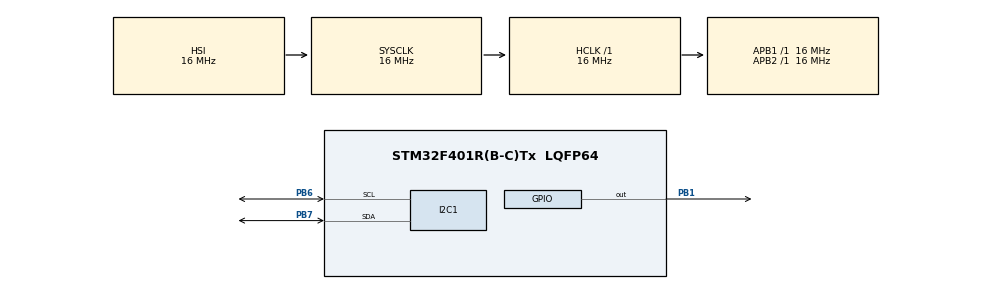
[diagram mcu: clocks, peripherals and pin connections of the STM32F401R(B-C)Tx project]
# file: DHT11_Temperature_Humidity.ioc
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Mcu.Family=STM32F4
Mcu.Name=STM32F401R(B-C)Tx
Mcu.Package=LQFP64
NVIC.PriorityGroup=NVIC_PRIORITYGROUP_4
PA13.Mode=Serial_Wire
PA13.Signal=SYS_JTMS-SWDIO
PA14.Mode=Serial_Wire
PA14.Signal=SYS_JTCK-SWCLK
PB1.Signal=GPIO_Output
PB6.Mode=I2C
PB6.Signal=I2C1_SCL
PB7.Mode=I2C
PB7.Signal=I2C1_SDA
ProjectManager.HeapSize=0x200
ProjectManager.StackSize=0x400
ProjectManager.TargetToolchain=STM32CubeIDE
RCC.AHBFreq_Value=16000000
RCC.APB1Freq_Value=16000000
RCC.APB2Freq_Value=16000000
RCC.CortexFreq_Value=16000000
RCC.HSE_VALUE=25000000
RCC.HSI_VALUE=16000000
RCC.LSE_VALUE=32768
RCC.SYSCLKFreq_VALUE=16000000
RCC.VCOOutputFreq_Value=192000000
TIM2.Period=65535
TIM2.Prescaler=15
VP_TIM2_VS_ClockSourceINT.Mode=Internal
board=custom

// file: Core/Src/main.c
/* USER CODE BEGIN Header */
/**
  ******************************************************************************
  * @file           : main.c
  * @brief          : Main program body
  ******************************************************************************
  * @attention
  *
  * Copyright (c) 2026 STMicroelectronics.
  * All rights reserved.
  *
  * This software is licensed under terms that can be found in the LICENSE file
  * in the root directory of this software component.
  * If no LICENSE file comes with this software, it is provided AS-IS.
  *
  ******************************************************************************
  */
/* USER CODE END Header */
#include "main.h"
#include <stdio.h>
#include "ssd1306.h"
#include "ssd1306_fonts.h"

I2C_HandleTypeDef hi2c1;

TIM_HandleTypeDef htim2;

/* USER CODE BEGIN PV */
uint8_t humidity = 0;
uint8_t temperature = 0;
uint8_t dht_status = 0;

char oled_text[32];
/* USER CODE END PV */

void SystemClock_Config(void);
static void MX_GPIO_Init(void);
static void MX_I2C1_Init(void);
static void MX_TIM2_Init(void);
/* USER CODE BEGIN PFP */
void delay_us(uint16_t us);
void DHT11_SetPinOutput(void);
void DHT11_SetPinInput(void);
uint8_t DHT11_ReadByte(void);
uint8_t DHT11_Read(uint8_t *temp, uint8_t *hum);
/* USER CODE END PFP */

/* USER CODE BEGIN 0 */
void delay_us(uint16_t us)
{
    __HAL_TIM_SET_COUNTER(&htim2, 0);

    while (__HAL_TIM_GET_COUNTER(&htim2) < us)
    {
    }
}

void DHT11_SetPinOutput(void)
{
    GPIO_InitTypeDef GPIO_InitStruct = {0};

    GPIO_InitStruct.Pin = GPIO_PIN_1;
    GPIO_InitStruct.Mode = GPIO_MODE_OUTPUT_OD;
    GPIO_InitStruct.Pull = GPIO_NOPULL;
    GPIO_InitStruct.Speed = GPIO_SPEED_FREQ_LOW;

    HAL_GPIO_Init(GPIOB, &GPIO_InitStruct);
}

void DHT11_SetPinInput(void)
{
    GPIO_InitTypeDef GPIO_InitStruct = {0};

    GPIO_InitStruct.Pin = GPIO_PIN_1;
    GPIO_InitStruct.Mode = GPIO_MODE_INPUT;
    GPIO_InitStruct.Pull = GPIO_NOPULL;

    HAL_GPIO_Init(GPIOB, &GPIO_InitStruct);
}

uint8_t DHT11_ReadByte(void)
{
    uint8_t value = 0;

    for (uint8_t i = 0; i < 8; i++)
    {
        uint32_t timeout = 0;

        /* DHT11 hattı HIGH olana kadar bekle */
        while (HAL_GPIO_ReadPin(GPIOB, GPIO_PIN_1) == GPIO_PIN_RESET)
        {
            timeout++;

            if (timeout > 10000)
            {
                return 0;
            }
        }

        /*
         * Yaklaşık 40 us sonra hattı oku.
         * Bit 0 ise HIGH süresi yaklaşık 26-28 us,
         * bit 1 ise yaklaşık 70 us sürer.
         */
        delay_us(40);

        value <<= 1;

        if (HAL_GPIO_ReadPin(GPIOB, GPIO_PIN_1) == GPIO_PIN_SET)
        {
            value |= 1;
        }

        timeout = 0;

        /* Mevcut HIGH darbesinin bitmesini bekle */
        while (HAL_GPIO_ReadPin(GPIOB, GPIO_PIN_1) == GPIO_PIN_SET)
        {
            timeout++;

            if (timeout > 10000)
            {
                break;
            }
        }
    }

    return value;
}

uint8_t DHT11_Read(uint8_t *temp, uint8_t *hum)
{
    uint8_t data[5] = {0};
    uint32_t timeout = 0;

    /* STM32 başlangıç sinyali gönderir */
    DHT11_SetPinOutput();

    HAL_GPIO_WritePin(GPIOB, GPIO_PIN_1, GPIO_PIN_RESET);
    HAL_Delay(18);

    HAL_GPIO_WritePin(GPIOB, GPIO_PIN_1, GPIO_PIN_SET);
    delay_us(30);

    /* Veri hattını DHT11'e bırak */
    DHT11_SetPinInput();

    /* DHT11'in yaklaşık 80 us LOW cevabını bekle */
    timeout = 0;

    while (HAL_GPIO_ReadPin(GPIOB, GPIO_PIN_1) == GPIO_PIN_SET)
    {
        timeout++;

        if (timeout > 10000)
        {
            return 0;
        }
    }

    /* LOW cevabının bitmesini bekle */
    timeout = 0;

    while (HAL_GPIO_ReadPin(GPIOB, GPIO_PIN_1) == GPIO_PIN_RESET)
    {
        timeout++;

        if (timeout > 10000)
        {
            return 0;
        }
    }

    /* Yaklaşık 80 us HIGH cevabının bitmesini bekle */
    timeout = 0;

    while (HAL_GPIO_ReadPin(GPIOB, GPIO_PIN_1) == GPIO_PIN_SET)
    {
        timeout++;

        if (timeout > 10000)
        {
            return 0;
        }
    }

    /* 40 bit = 5 byte oku */
    for (uint8_t i = 0; i < 5; i++)
    {
        data[i] = DHT11_ReadByte();
    }

    /* Checksum kontrolü */
    uint8_t checksum =
        data[0] +
        data[1] +
        data[2] +
        data[3];

    if (checksum != data[4])
    {
        return 0;
    }

    *hum = data[0];
    *temp = data[2];

    return 1;
}
/* USER CODE END 0 */

int main(void)
{

  /* MCU Configuration--------------------------------------------------------*/

  /* Reset of all peripherals, Initializes the Flash interface and the Systick. */
  HAL_Init();

  /* Configure the system clock */
  SystemClock_Config();

  /* Initialize all configured peripherals */
  MX_GPIO_Init();
  MX_I2C1_Init();
  MX_TIM2_Init();
  /* USER CODE BEGIN 2 */
  HAL_TIM_Base_Start(&htim2);

  ssd1306_Init();
  ssd1306_Fill(Black);

  ssd1306_SetCursor(5, 20);
  ssd1306_WriteString("DHT11 basliyor", Font_7x10, White);

  ssd1306_UpdateScreen();

  HAL_Delay(2000);
  /* USER CODE END 2 */

  /* Infinite loop */
  /* USER CODE BEGIN WHILE */
  while (1)
  {
	  dht_status = DHT11_Read(&temperature, &humidity);

	     ssd1306_Fill(Black);

	     if (dht_status == 1)
	     {
	         snprintf(
	             oled_text,
	             sizeof(oled_text),
	             "Sicaklik: %u C",
	             temperature
	         );

	         ssd1306_SetCursor(2, 15);
	         ssd1306_WriteString(oled_text, Font_7x10, White);

	         snprintf(
	             oled_text,
	             sizeof(oled_text),
	             "Nem: %u %%",
	             humidity
	         );

	         ssd1306_SetCursor(2, 35);
	         ssd1306_WriteString(oled_text, Font_7x10, White);
	     }
	     else
	     {
	         ssd1306_SetCursor(5, 25);
	         ssd1306_WriteString("DHT11 okuma hata", Font_7x10, White);
	     }

	     ssd1306_UpdateScreen();

	     HAL_Delay(2000);

    /* USER CODE END WHILE */

  }
}

void SystemClock_Config(void)
{
  RCC_OscInitTypeDef RCC_OscInitStruct = {0};
  RCC_ClkInitTypeDef RCC_ClkInitStruct = {0};

  /** Configure the main internal regulator output voltage
  */
  __HAL_RCC_PWR_CLK_ENABLE();
  __HAL_PWR_VOLTAGESCALING_CONFIG(PWR_REGULATOR_VOLTAGE_SCALE2);

  /** Initializes the RCC Oscillators according to the specified parameters
  * in the RCC_OscInitTypeDef structure.
  */
  RCC_OscInitStruct.OscillatorType = RCC_OSCILLATORTYPE_HSI;
  RCC_OscInitStruct.HSIState = RCC_HSI_ON;
  RCC_OscInitStruct.HSICalibrationValue = RCC_HSICALIBRATION_DEFAULT;
  RCC_OscInitStruct.PLL.PLLState = RCC_PLL_NONE;
  if (HAL_RCC_OscConfig(&RCC_OscInitStruct) != HAL_OK)
  {
    Error_Handler();
  }

  /** Initializes the CPU, AHB and APB buses clocks
  */
  RCC_ClkInitStruct.ClockType = RCC_CLOCKTYPE_HCLK|RCC_CLOCKTYPE_SYSCLK
                              |RCC_CLOCKTYPE_PCLK1|RCC_CLOCKTYPE_PCLK2;
  RCC_ClkInitStruct.SYSCLKSource = RCC_SYSCLKSOURCE_HSI;
  RCC_ClkInitStruct.AHBCLKDivider = RCC_SYSCLK_DIV1;
  RCC_ClkInitStruct.APB1CLKDivider = RCC_HCLK_DIV1;
  RCC_ClkInitStruct.APB2CLKDivider = RCC_HCLK_DIV1;

  if (HAL_RCC_ClockConfig(&RCC_ClkInitStruct, FLASH_LATENCY_0) != HAL_OK)
  {
    Error_Handler();
  }
}

static void MX_I2C1_Init(void)
{

  hi2c1.Instance = I2C1;
  hi2c1.Init.ClockSpeed = 100000;
  hi2c1.Init.DutyCycle = I2C_DUTYCYCLE_2;
  hi2c1.Init.OwnAddress1 = 0;
  hi2c1.Init.AddressingMode = I2C_ADDRESSINGMODE_7BIT;
  hi2c1.Init.DualAddressMode = I2C_DUALADDRESS_DISABLE;
  hi2c1.Init.OwnAddress2 = 0;
  hi2c1.Init.GeneralCallMode = I2C_GENERALCALL_DISABLE;
  hi2c1.Init.NoStretchMode = I2C_NOSTRETCH_DISABLE;
  if (HAL_I2C_Init(&hi2c1) != HAL_OK)
  {
    Error_Handler();
  }

}

static void MX_TIM2_Init(void)
{

  TIM_ClockConfigTypeDef sClockSourceConfig = {0};
  TIM_MasterConfigTypeDef sMasterConfig = {0};

  htim2.Instance = TIM2;
  htim2.Init.Prescaler = 15;
  htim2.Init.CounterMode = TIM_COUNTERMODE_UP;
  htim2.Init.Period = 65535;
  htim2.Init.ClockDivision = TIM_CLOCKDIVISION_DIV1;
  htim2.Init.AutoReloadPreload = TIM_AUTORELOAD_PRELOAD_DISABLE;
  if (HAL_TIM_Base_Init(&htim2) != HAL_OK)
  {
    Error_Handler();
  }
  sClockSourceConfig.ClockSource = TIM_CLOCKSOURCE_INTERNAL;
  if (HAL_TIM_ConfigClockSource(&htim2, &sClockSourceConfig) != HAL_OK)
  {
    Error_Handler();
  }
  sMasterConfig.MasterOutputTrigger = TIM_TRGO_RESET;
  sMasterConfig.MasterSlaveMode = TIM_MASTERSLAVEMODE_DISABLE;
  if (HAL_TIMEx_MasterConfigSynchronization(&htim2, &sMasterConfig) != HAL_OK)
  {
    Error_Handler();
  }

}

static void MX_GPIO_Init(void)
{
  GPIO_InitTypeDef GPIO_InitStruct = {0};

  /* GPIO Ports Clock Enable */
  __HAL_RCC_GPIOB_CLK_ENABLE();
  __HAL_RCC_GPIOA_CLK_ENABLE();

  /*Configure GPIO pin Output Level */
  HAL_GPIO_WritePin(GPIOB, GPIO_PIN_1, GPIO_PIN_RESET);

  /*Configure GPIO pin : PB1 */
  GPIO_InitStruct.Pin = GPIO_PIN_1;
  GPIO_InitStruct.Mode = GPIO_MODE_OUTPUT_PP;
  GPIO_InitStruct.Pull = GPIO_NOPULL;
  GPIO_InitStruct.Speed = GPIO_SPEED_FREQ_LOW;
  HAL_GPIO_Init(GPIOB, &GPIO_InitStruct);

}

void Error_Handler(void)
{
  __disable_irq();
  while (1)
  {
  }
}
